# K210 register map
Vendor: Canaan Inc.; File version: 1.0
Registers are 32-bit, read-write, reset 0x0 unless marked. A register's access mark holds for its fields unless they carry their own. Offsets are from the block's base; [hi:lo] are bit positions; lines under a group give offsets from that group; {n}, {i} and the like mark numbered series; 'fields as' and 'values as' point back to an identical list.

## SPI0 — Serial Peripheral Interface 0 (master)
Base 0x52000000
Same registers: SPI1 0x53000000
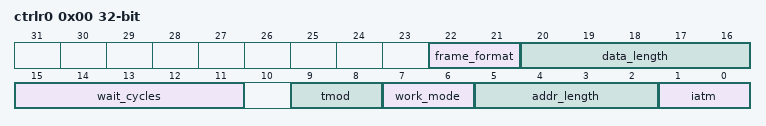
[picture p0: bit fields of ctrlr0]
0x00 ctrlr0 — Control Register 0
  [22:21] frame_format
    0=standard; 1=dual; 2=quad; 3=octal
  [20:16] data_length range 4..31 — DATA_BIT_LENGTH
  [15:11] wait_cycles
  [9:8] tmod — TRANSFER_MODE
    0=trans_recv; 1=trans; 2=recv; 3=eerom
  [7:6] work_mode
    {v}=mode{v} (v=0..3)
  [5:2] addr_length range 0..3
  [1:0] iatm — instruction_address_trans_mode
    0=standard; 1=addr_standard; 2=as_frame_format
0x04 ctrlr1 — Control Register 1
0x08 ssienr — Enable Register
0x0C mwcr — Microwire Control Register
0x10 ser — Slave Enable Register
0x14 baudr — Baud Rate Select
0x18 txftlr — Transmit FIFO Threshold Level
0x1C rxftlr — Receive FIFO Threshold Level
0x20 txflr — Transmit FIFO Level Register
0x24 rxflr — Receive FIFO Level Register
0x28 sr — Status Register
0x2C imr — Interrupt Mask Register
0x30 isr — Interrupt Status Register
0x34 risr — Raw Interrupt Status Register
0x38 txoicr — Transmit FIFO Overflow Interrupt Clear Register
0x3C rxoicr — Receive FIFO Overflow Interrupt Clear Register
0x40 rxuicr — Receive FIFO Underflow Interrupt Clear Register
0x44 msticr — Multi-Master Interrupt Clear Register
0x48 icr — Interrupt Clear Register
0x4C dmacr — DMA Control Register
0x50 dmatdlr — DMA Transmit Data Level
0x54 dmardlr — DMA Receive Data Level
0x58 idr — Identification Register
0x5C ssic_version_id — DWC_ssi component version
{0x60+4i} dr{i} (i=0..35) — Data Register
0xF0 rx_sample_delay
0xF4 spi_ctrlr0 — SPI Control Register
0xFC xip_mode_bits
0x100 xip_incr_inst — XIP INCR transfer opcode
0x104 xip_wrap_inst — XIP WRAP transfer opcode
0x108 xip_ctrl — XIP Control Register
0x10C xip_ser — XIP Slave Enable Register
0x110 xrxoicr — XIP Receive FIFO Overflow Interrupt Clear Register
0x114 xip_cnt_time_out — XIP time out register for continuous transfers
0x118 endian

## I2S0 — Inter-Integrated Sound Interface 0
Base 0x50250000
Same registers: I2S1 0x50260000, I2S2 0x50270000
0x00 ier — Enable Register
  [0] ien — I2S Enable
    0=disable; 1=enable
0x04 irer — Receiver Block Enable Register
  [0] rxen — Receiver block enable
    0=disable; 1=enable
0x08 iter — Transmitter Block Enable Register
  [0] txen — Transmitter block enable
    0=disable; 1=enable
0x0C cer — Clock Generation enable
  [0] clken — Transmitter block enable
    0=disable; 1=enable
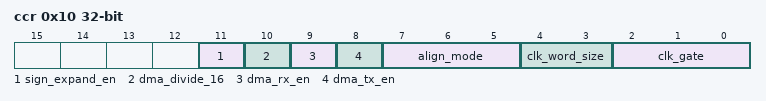
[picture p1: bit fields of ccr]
0x10 ccr — Clock Configuration Register
  [11] sign_expand_en
    0=disable; 1=enable
  [10] dma_divide_16 — Split 32bit data to two 16 bit data and filled in left and right channel. Used with dma_tx_en or dma_rx_en
    0=disable; 1=enable
  [9] dma_rx_en — DMA receive enable control
    0=disable; 1=enable
  [8] dma_tx_en — DMA transmit enable control
    0=disable; 1=enable
  [7:5] align_mode — Alignment mode setting
    1=Standard I2S format; 2=Right aligned format; 4=Left aligned format
  [4:3] clk_word_size — The number of sclk cycles for which the word select line stayd in the left aligned or right aligned mode
    0=cycles16 (16 sclk cycles); 1=cycles24 (24 sclk cycles); 2=cycles32 (32 sclk cycles)
  [2:0] clk_gate — Gating of sclk
    0=no (Clock gating is disable); 1=cycles12 (Gating after 12 sclk cycles); 2=cycles16 (Gating after 16 sclk cycles); 3=cycles20 (Gating after 20 sclk cycles); 4=cycles24 (Gating after 24 sclk cycles)
0x14 rxffr — Receiver Block FIFO Reset Register
  [0] rxffr — Receiver FIFO reset
    0=Not flush FIFO; 1=Flush FIFO
0x18 txffr — Transmitter Block FIFO Reset Register
  [0] rxffr — Transmitter FIFO reset
    0=Not flush FIFO; 1=Flush FIFO
{0x20+0x40*i} channel{i} (i=0..3) group — Channel cluster
  0x00 left_rxtx — Left Receive or Left Transmit Register
  0x04 right_rxtx — Right Receive or Right Transmit Register
  0x08 rer — Receive Enable Register
    [0] rxchenx — Receive channel enable/disable
      0=disable; 1=enable
  0x0C ter — Transmit Enable Register
    [0] txchenx — Transmit channel enable/disable
      0=disable; 1=enable
  0x10 rcr — Receive Configuration Register
    [2:0] wlen — Desired data resolution of receiver
      0=Ignore the word length; 1=resolution12 (12-bit data resolution of the receiver); 2=resolution16 (16-bit data resolution of the receiver); 3=resolution20 (20-bit data resolution of the receiver); 4=resolution24 (24-bit data resolution of the receiver); 5=resolution32 (32-bit data resolution of the receiver)
  0x14 tcr — Transmit Configuration Register
    [2:0] wlen — Desired data resolution of transmitter
      values as channel0.rcr.wlen
  0x18 isr — Interrupt Status Register
  0x1C imr — Interrupt Mask Register
  0x20 ror — Receive Overrun Register
  0x24 tor — Transmit Overrun Register
  0x28 rfcr — Receive FIFO Configuration Register
  0x2C tfcr — Transmit FIFO Configuration Register
  0x30 rff — Receive FIFO Flush Register
  0x34 tff — Transmit FIFO Flush Register
  {0x38+4j} _reserved{j} (j=0..1) — _RESERVED0
0x1C0 rxdma — Receiver Block DMA Register
0x1C4 rrxdma — Reset Receiver Block DMA Register
0x1C8 txdma — Transmitter Block DMA Register
0x1CC rtxdma — Reset Transmitter Block DMA Register
0x1F0 i2s_comp_param_2 — Component Parameter Register 2
0x1F4 i2s_comp_param_1 — Component Parameter Register 1
0x1F8 i2s_comp_version_1 — Component Version Register
0x1FC i2s_comp_type — Component Type Register
